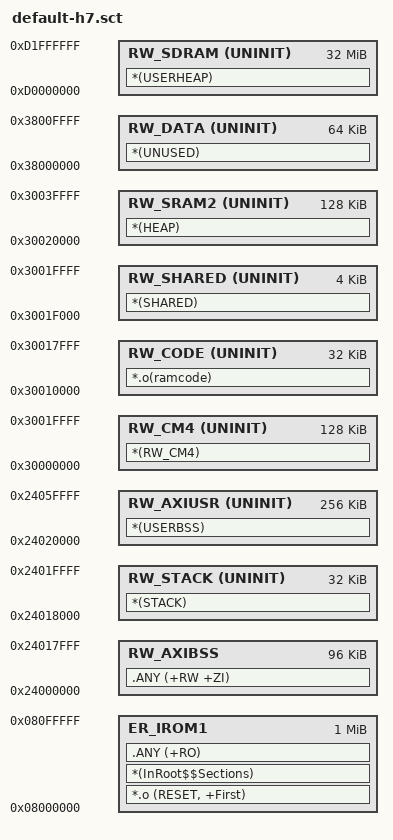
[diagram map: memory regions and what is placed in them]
; *************************************************************
; *** Scatter-Loading Description File generated by uVision ***
; *************************************************************

LR_IROM1 0x08000000 0x00100000  {    ; load region size_region
  ER_IROM1 0x08000000 0x00100000  {  ; load address = execution address
   *.o (RESET, +First)
   *(InRoot$$Sections)
   .ANY (+RO)
  }
  RW_DATA 0x38000000 UNINIT 0x00010000  { ;SRAM1
   *(UNUSED)
  }
  RW_CM4 0x30000000 UNINIT 0x00020000  { ;SRAM1
   *(RW_CM4)
  }
  RW_CODE 0x30010000 UNINIT 0x00008000  { ;SRAM1
   *.o(ramcode)
  }
  RW_SHARED 0x3001f000 UNINIT 0x00001000  { ;SRAM1
   *(SHARED)
  }
  RW_SRAM2 0x30020000 UNINIT 0x00020000  { ;SRAM2
    *(HEAP)
  }
  RW_AXIBSS 0x24000000 0x00018000  { ;AXI SRAM
   .ANY (+RW +ZI)
  }
  RW_STACK 0x24018000 UNINIT 0x00008000  { ;SRAM2
   *(STACK)
  }
  RW_AXIUSR 0x24020000 UNINIT 0x00040000  { ;AXI SRAM
   *(USERBSS)
  }
  RW_SDRAM 0xD0000000 UNINIT 0x02000000  {  ; SDRAM
   *(USERHEAP)
  }
}
;0x38800000 - 0x38800FFF Backup SRAM
;0x38000000 - 0x3800FFFF SRAM4, SMP shared
;0x30040000 - 0x30047FFF SRAM3, SMP shared
;0x30020000 - 0x3003FFFF SRAM2
;0x30000000 - 0x3001FFFF SRAM1
;0x24000000 - 0x2407FFFF AXI SRAM
;0x20000000 - 0x2001FFFF DTCM (Only M7 core)
;0x00000000 - 0x0000FFFF M7 - ITCM; M4 - VTOR REMAP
